AUTOSAR XML (schema 00052)
package /Components
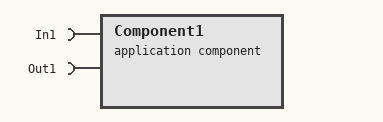
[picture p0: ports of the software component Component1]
  application sw component type Component1
    require port In1
    require port Out1
